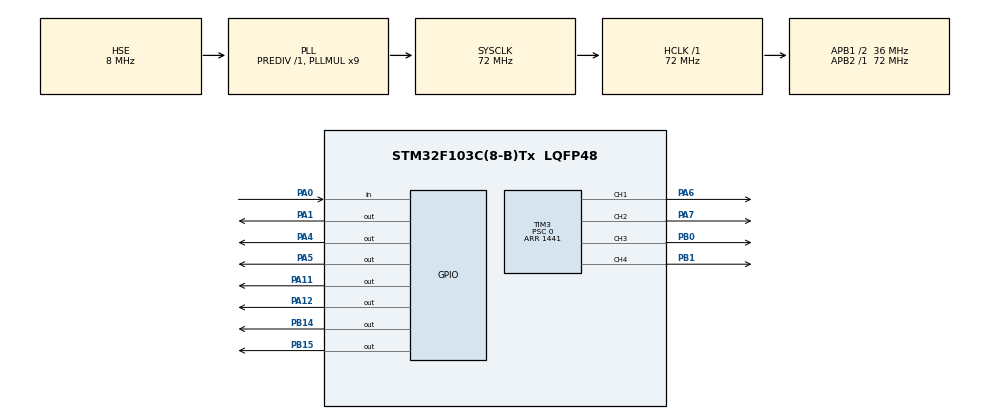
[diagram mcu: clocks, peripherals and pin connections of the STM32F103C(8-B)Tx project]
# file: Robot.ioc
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FREERTOS.Tasks01=defaultTask,0,128,StartDefaultTask,Default,NULL,Dynamic,NULL,NULL
Mcu.Family=STM32F1
Mcu.Name=STM32F103C(8-B)Tx
Mcu.Package=LQFP48
NVIC.PriorityGroup=NVIC_PRIORITYGROUP_4
PA0-WKUP.GPIO_PuPd=GPIO_PULLDOWN
PA0-WKUP.Signal=GPIO_Input
PA1.Signal=GPIO_Output
PA11.Signal=GPIO_Output
PA12.Signal=GPIO_Output
PA4.Signal=GPIO_Output
PA5.Signal=GPIO_Output
PA6.Signal=S_TIM3_CH1
PA7.Signal=S_TIM3_CH2
PB0.Signal=S_TIM3_CH3
PB1.Signal=S_TIM3_CH4
PB14.Signal=GPIO_Output
PB15.Signal=GPIO_Output
PD0-OSC_IN.Mode=HSE-External-Oscillator
PD0-OSC_IN.Signal=RCC_OSC_IN
PD1-OSC_OUT.Mode=HSE-External-Oscillator
PD1-OSC_OUT.Signal=RCC_OSC_OUT
ProjectManager.HeapSize=0x200
ProjectManager.StackSize=0x400
ProjectManager.TargetToolchain=MDK-ARM V5.32
RCC.AHBFreq_Value=72000000
RCC.APB1CLKDivider=RCC_HCLK_DIV2
RCC.APB1Freq_Value=36000000
RCC.APB1TimFreq_Value=72000000
RCC.APB2Freq_Value=72000000
RCC.APB2TimFreq_Value=72000000
RCC.HCLKFreq_Value=72000000
RCC.PLLMUL=RCC_PLL_MUL9
RCC.PLLSourceVirtual=RCC_PLLSOURCE_HSE
RCC.SYSCLKFreq_VALUE=72000000
RCC.SYSCLKSource=RCC_SYSCLKSOURCE_PLLCLK
RCC.USBFreq_Value=72000000
SH.S_TIM3_CH1.0=TIM3_CH1,PWM Generation1 CH1
SH.S_TIM3_CH2.0=TIM3_CH2,PWM Generation2 CH2
SH.S_TIM3_CH3.0=TIM3_CH3,PWM Generation3 CH3
SH.S_TIM3_CH4.0=TIM3_CH4,PWM Generation4 CH4
TIM3.Channel-PWM\ Generation1\ CH1=TIM_CHANNEL_1
TIM3.Channel-PWM\ Generation2\ CH2=TIM_CHANNEL_2
TIM3.Channel-PWM\ Generation3\ CH3=TIM_CHANNEL_3
TIM3.Channel-PWM\ Generation4\ CH4=TIM_CHANNEL_4
TIM3.OCMode_PWM-PWM\ Generation1\ CH1=TIM_OCMODE_PWM1
TIM3.Period=1441
TIM3.Prescaler=0
VP_FREERTOS_VS_CMSIS_V1.Mode=CMSIS_V1
VP_SYS_VS_ND.Mode=No_Debug
board=custom

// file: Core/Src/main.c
/* USER CODE BEGIN Header */
/**
  ******************************************************************************
  * @file           : main.c
  * @brief          : Main program body
  ******************************************************************************
  * @attention
  *
  * Copyright (c) 2023 STMicroelectronics.
  * All rights reserved.
  *
  * This software is licensed under terms that can be found in the LICENSE file
  * in the root directory of this software component.
  * If no LICENSE file comes with this software, it is provided AS-IS.
  *
  ******************************************************************************
  */
/* USER CODE END Header */
#include "main.h"
#include "cmsis_os.h"

TIM_HandleTypeDef htim3;

osThreadId defaultTaskHandle;
/* USER CODE BEGIN PV */
osThreadId Chassis_TaskHandle;
osThreadId Remote_TaskHandle;
/* USER CODE END PV */

void SystemClock_Config(void);
static void MX_GPIO_Init(void);
static void MX_TIM3_Init(void);
void StartDefaultTask(void const * argument);

/* USER CODE BEGIN PFP */
void Remote_Task(void const * argument);
void Chassis_Task(void const * argument);
/* USER CODE END PFP */

int main(void)
{

  /* MCU Configuration--------------------------------------------------------*/

  /* Reset of all peripherals, Initializes the Flash interface and the Systick. */
  HAL_Init();

  /* Configure the system clock */
  SystemClock_Config();

  /* Initialize all configured peripherals */
  MX_GPIO_Init();
  MX_TIM3_Init();
  /* USER CODE BEGIN 2 */

  /*硬件初始化*/

  //PWM初始化
  HAL_TIM_PWM_Init(&htim3);
  HAL_TIM_PWM_Start(&htim3,TIM_CHANNEL_1);
  HAL_TIM_PWM_Start(&htim3,TIM_CHANNEL_2);
  HAL_TIM_PWM_Start(&htim3,TIM_CHANNEL_3);
  HAL_TIM_PWM_Start(&htim3,TIM_CHANNEL_4);

  /* USER CODE END 2 */

  /* Create the thread(s) */
  /* definition and creation of defaultTask */
  osThreadDef(defaultTask, StartDefaultTask, osPriorityNormal, 0, 128);
  defaultTaskHandle = osThreadCreate(osThread(defaultTask), NULL);

  /* USER CODE BEGIN RTOS_THREADS */
  //底盘任务
  osThreadDef(Chassis_Task, Chassis_Task, osPriorityHigh, 0, 128);
  Chassis_TaskHandle = osThreadCreate(osThread(Chassis_Task), NULL);
  //遥控任务
  osThreadDef(Remote_Task, Remote_Task, osPriorityHigh, 0, 128);
  Remote_TaskHandle = osThreadCreate(osThread(Remote_Task), NULL);

  /* USER CODE END RTOS_THREADS */

  /* Start scheduler */
  osKernelStart();

  /* We should never get here as control is now taken by the scheduler */
  /* Infinite loop */
  while (1)
  {

  }
}

void SystemClock_Config(void)
{
  RCC_OscInitTypeDef RCC_OscInitStruct = {0};
  RCC_ClkInitTypeDef RCC_ClkInitStruct = {0};

  /** Initializes the RCC Oscillators according to the specified parameters
  * in the RCC_OscInitTypeDef structure.
  */
  RCC_OscInitStruct.OscillatorType = RCC_OSCILLATORTYPE_HSE;
  RCC_OscInitStruct.HSEState = RCC_HSE_ON;
  RCC_OscInitStruct.HSEPredivValue = RCC_HSE_PREDIV_DIV1;
  RCC_OscInitStruct.HSIState = RCC_HSI_ON;
  RCC_OscInitStruct.PLL.PLLState = RCC_PLL_ON;
  RCC_OscInitStruct.PLL.PLLSource = RCC_PLLSOURCE_HSE;
  RCC_OscInitStruct.PLL.PLLMUL = RCC_PLL_MUL9;
  if (HAL_RCC_OscConfig(&RCC_OscInitStruct) != HAL_OK)
  {
    Error_Handler();
  }

  /** Initializes the CPU, AHB and APB buses clocks
  */
  RCC_ClkInitStruct.ClockType = RCC_CLOCKTYPE_HCLK|RCC_CLOCKTYPE_SYSCLK
                              |RCC_CLOCKTYPE_PCLK1|RCC_CLOCKTYPE_PCLK2;
  RCC_ClkInitStruct.SYSCLKSource = RCC_SYSCLKSOURCE_PLLCLK;
  RCC_ClkInitStruct.AHBCLKDivider = RCC_SYSCLK_DIV1;
  RCC_ClkInitStruct.APB1CLKDivider = RCC_HCLK_DIV2;
  RCC_ClkInitStruct.APB2CLKDivider = RCC_HCLK_DIV1;

  if (HAL_RCC_ClockConfig(&RCC_ClkInitStruct, FLASH_LATENCY_2) != HAL_OK)
  {
    Error_Handler();
  }
}

static void MX_TIM3_Init(void)
{

  TIM_MasterConfigTypeDef sMasterConfig = {0};
  TIM_OC_InitTypeDef sConfigOC = {0};

  htim3.Instance = TIM3;
  htim3.Init.Prescaler = 0;
  htim3.Init.CounterMode = TIM_COUNTERMODE_UP;
  htim3.Init.Period = 1441;
  htim3.Init.ClockDivision = TIM_CLOCKDIVISION_DIV1;
  htim3.Init.AutoReloadPreload = TIM_AUTORELOAD_PRELOAD_DISABLE;
  if (HAL_TIM_PWM_Init(&htim3) != HAL_OK)
  {
    Error_Handler();
  }
  sMasterConfig.MasterOutputTrigger = TIM_TRGO_RESET;
  sMasterConfig.MasterSlaveMode = TIM_MASTERSLAVEMODE_DISABLE;
  if (HAL_TIMEx_MasterConfigSynchronization(&htim3, &sMasterConfig) != HAL_OK)
  {
    Error_Handler();
  }
  sConfigOC.OCMode = TIM_OCMODE_PWM1;
  sConfigOC.Pulse = 0;
  sConfigOC.OCPolarity = TIM_OCPOLARITY_HIGH;
  sConfigOC.OCFastMode = TIM_OCFAST_DISABLE;
  if (HAL_TIM_PWM_ConfigChannel(&htim3, &sConfigOC, TIM_CHANNEL_1) != HAL_OK)
  {
    Error_Handler();
  }
  if (HAL_TIM_PWM_ConfigChannel(&htim3, &sConfigOC, TIM_CHANNEL_2) != HAL_OK)
  {
    Error_Handler();
  }
  if (HAL_TIM_PWM_ConfigChannel(&htim3, &sConfigOC, TIM_CHANNEL_3) != HAL_OK)
  {
    Error_Handler();
  }
  if (HAL_TIM_PWM_ConfigChannel(&htim3, &sConfigOC, TIM_CHANNEL_4) != HAL_OK)
  {
    Error_Handler();
  }
  HAL_TIM_MspPostInit(&htim3);

}

static void MX_GPIO_Init(void)
{
  GPIO_InitTypeDef GPIO_InitStruct = {0};

  /* GPIO Ports Clock Enable */
  __HAL_RCC_GPIOD_CLK_ENABLE();
  __HAL_RCC_GPIOA_CLK_ENABLE();
  __HAL_RCC_GPIOB_CLK_ENABLE();

  /*Configure GPIO pin Output Level */
  HAL_GPIO_WritePin(GPIOA, GPIO_PIN_1|GPIO_PIN_4|GPIO_PIN_5|GPIO_PIN_11
                          |GPIO_PIN_12, GPIO_PIN_RESET);

  /*Configure GPIO pin Output Level */
  HAL_GPIO_WritePin(GPIOB, GPIO_PIN_14|GPIO_PIN_15, GPIO_PIN_RESET);

  /*Configure GPIO pin : PA0 */
  GPIO_InitStruct.Pin = GPIO_PIN_0;
  GPIO_InitStruct.Mode = GPIO_MODE_INPUT;
  GPIO_InitStruct.Pull = GPIO_PULLDOWN;
  HAL_GPIO_Init(GPIOA, &GPIO_InitStruct);

  /*Configure GPIO pins : PA1 PA4 PA5 PA11
                           PA12 */
  GPIO_InitStruct.Pin = GPIO_PIN_1|GPIO_PIN_4|GPIO_PIN_5|GPIO_PIN_11
                          |GPIO_PIN_12;
  GPIO_InitStruct.Mode = GPIO_MODE_OUTPUT_PP;
  GPIO_InitStruct.Pull = GPIO_NOPULL;
  GPIO_InitStruct.Speed = GPIO_SPEED_FREQ_LOW;
  HAL_GPIO_Init(GPIOA, &GPIO_InitStruct);

  /*Configure GPIO pins : PB14 PB15 */
  GPIO_InitStruct.Pin = GPIO_PIN_14|GPIO_PIN_15;
  GPIO_InitStruct.Mode = GPIO_MODE_OUTPUT_PP;
  GPIO_InitStruct.Pull = GPIO_NOPULL;
  GPIO_InitStruct.Speed = GPIO_SPEED_FREQ_LOW;
  HAL_GPIO_Init(GPIOB, &GPIO_InitStruct);

}

void StartDefaultTask(void const * argument)
{
  for(;;)
  {
    osDelay(1);
  }
}

void Error_Handler(void)
{
  __disable_irq();
  while (1)
  {
  }
}
